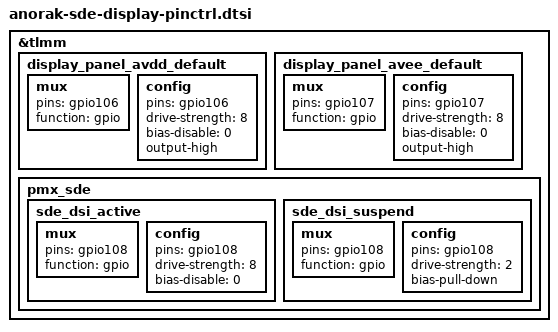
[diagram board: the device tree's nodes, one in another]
&tlmm {
	display_panel_avdd_default: display_panel_avdd_default {
		mux {
			pins = "gpio106";
			function = "gpio";
		};

		config {
			pins = "gpio106";
			drive-strength = <8>;
			bias-disable = <0>;
			output-high;
		};
	};

	display_panel_avee_default: display_panel_avee_default {
		mux {
			pins = "gpio107";
			function = "gpio";
		};

		config {
			pins = "gpio107";
			drive-strength = <8>;
			bias-disable = <0>;
			output-high;
		};
	};

	pmx_sde: pmx_sde {
		sde_dsi_active: sde_dsi_active {
			mux {
				pins = "gpio108";
				function = "gpio";
			};

			config {
				pins = "gpio108";
				drive-strength = <8>;   /* 8 mA */
				bias-disable = <0>;   /* no pull */
			};
		};

		sde_dsi_suspend: sde_dsi_suspend {
			mux {
				pins = "gpio108";
				function = "gpio";
			};

			config {
				pins = "gpio108";
				drive-strength = <2>;   /* 2 mA */
				bias-pull-down;         /* PULL DOWN */
			};
		};
	};
};
